AUTOSAR XML (schema 314)
package /ComponentType
  internal behavior Sa_MtrPos3_InternalBehavior: component=Sa_MtrPos3
    timing event TMT_MtrPos3_Per1: start-on-event=MtrPos3_Per1, period=0.002
    timing event TMT_MtrPos3_Per2: start-on-event=MtrPos3_Per2, period=0.004
    port-api-options:
      enable-take-address=false, indirect-api=false, port=CorrectedMtrPos
      enable-take-address=false, indirect-api=false, port=InvCos2Scaled
      enable-take-address=false, indirect-api=false, port=InvSin2Scaled
      enable-take-address=false, indirect-api=false, port=MtrPos3_Per2_CP1
      enable-take-address=false, indirect-api=false, port=NxtrDiagMgr
    runnable MtrPos3_Per1
      data read access READ_InvCos2Scaled_Volt_f32: data-element=InvCos2Scaled.Volt_f32
      data read access READ_InvSin2Scaled_Volt_f32: data-element=InvSin2Scaled.Volt_f32
    runnable MtrPos3_Per2
      data read access READ_CorrectedMtrPos_Rev_f32: data-element=CorrectedMtrPos.Rev_f32
      data read access READ_InvCos2Scaled_Volt_f32: data-element=InvCos2Scaled.Volt_f32
      data read access READ_InvSin2Scaled_Volt_f32: data-element=InvSin2Scaled.Volt_f32
      sync call SC_MtrPos3_Per2_CP1_CheckpointReached: operation=MtrPos3_Per2_CP1.CheckpointReached, timeout=0
      sync call SC_NxtrDiagMgr_SetNTCStatus: operation=NxtrDiagMgr.SetNTCStatus, timeout=0
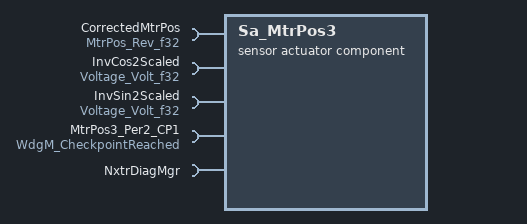
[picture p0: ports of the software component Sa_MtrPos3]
  sensor actuator software component type Sa_MtrPos3
    5 x require port:
      CorrectedMtrPos: unqueued-receiver-com-spec{data-element=Rev_f32, init-value=D_ZERO_ULS_F32}, required-interface=MtrPos_Rev_f32
      InvCos2Scaled: unqueued-receiver-com-spec{data-element=Volt_f32, init-value=D_ZERO_ULS_F32}, required-interface=Voltage_Volt_f32
      InvSin2Scaled: unqueued-receiver-com-spec{data-element=Volt_f32, init-value=D_ZERO_ULS_F32}, required-interface=Voltage_Volt_f32
      MtrPos3_Per2_CP1: client-com-spec=CheckpointReached, required-interface=WdgM_CheckpointReached
      NxtrDiagMgr: required-com-specs=[GetNTCActive, GetNTCFailed, GetNTCStatus, SetNTCStatus], required-interface=NxtrDiagMgr
  swc implementation Sa_MtrPos3_Implementation: behavior=Sa_MtrPos3_InternalBehavior
    code-descriptors:
      code Code: type=SRC
